# R7FA4L1BD register map
Vendor: Renesas Electronics Corporation; Series: RA4; File version: 0.90.02
CPU: CM33 r0p4, little endian, MPU, FPU, VTOR, 4 interrupt priority bits, 96 interrupts
Registers are 32-bit, read-write, reset 0x0 unless marked. A register's access mark holds for its fields unless they carry their own. Offsets are from the block's base; [hi:lo] are bit positions; {n}, {i} and the like mark numbered series.

## ICU — Interrupt Controller
Base 0x40006000
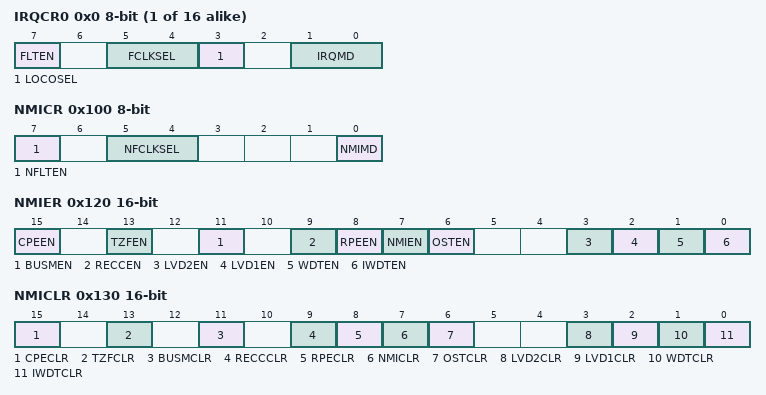
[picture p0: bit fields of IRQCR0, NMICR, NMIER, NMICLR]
{0x0+i} IRQCR{i} (i=0..15) 8-bit — IRQ Control Register {i}
  [7] FLTEN — IRQi Digital Filter Enable
  [5:4] FCLKSEL — IRQi Digital Filter Sampling Clock Select
  [3] LOCOSEL
  [1:0] IRQMD — IRQi Detection Sense Select
0x100 NMICR 8-bit — NMI Pin Interrupt Control Register
  [7] NFLTEN — NMI Digital Filter Enable
  [5:4] NFCLKSEL — NMI Digital Filter Sampling Clock Select
  [0] NMIMD — NMI Detection Set
0x120 NMIER 16-bit — Non,Maskable Interrupt Enable Register
  [15] CPEEN
  [13] TZFEN
  [11] BUSMEN — Bus Master MPU Error Interrupt Enable
  [9] RECCEN — SRAM ECC Error Interrupt Enable
  [8] RPEEN — SRAM Parity Error Interrupt Enable
  [7] NMIEN — NMI Pin Interrupt Enable
  [6] OSTEN — Main Clock Oscillation Stop Detection Interrupt Enable
  [3] LVD2EN — Voltage monitor 2 Interrupt Enable
  [2] LVD1EN — Voltage monitor 1 Interrupt Enable
  [1] WDTEN — WDT Underflow/Refresh Error Interrupt Enable
  [0] IWDTEN — IWDT Underflow/Refresh Error Interrupt Enable
0x130 NMICLR 16-bit — Non,Maskable Interrupt Status Clear Register
  [15] CPECLR
  [13] TZFCLR
  [11] BUSMCLR — Bus Master MPU Error Interrupt Status Flag Clear
  [9] RECCCLR — SRAM ECC Error Interrupt Status Flag Clear
  [8] RPECLR — SRAM Parity Error Interrupt Status Flag Clear
  [7] NMICLR — NMI Pin Interrupt Status Flag Clear
  [6] OSTCLR — Oscillation Stop Detection Interrupt Status Flag Clear
  [3] LVD2CLR — Voltage Monitor 2 Interrupt Status Flag Clear
  [2] LVD1CLR — Voltage Monitor 1 Interrupt Status Flag Clear
  [1] WDTCLR — WDT Underflow/Refresh Error Interrupt Status Flag Clear
  [0] IWDTCLR — IWDT Underflow/Refresh Error Interrupt Status Flag Clear
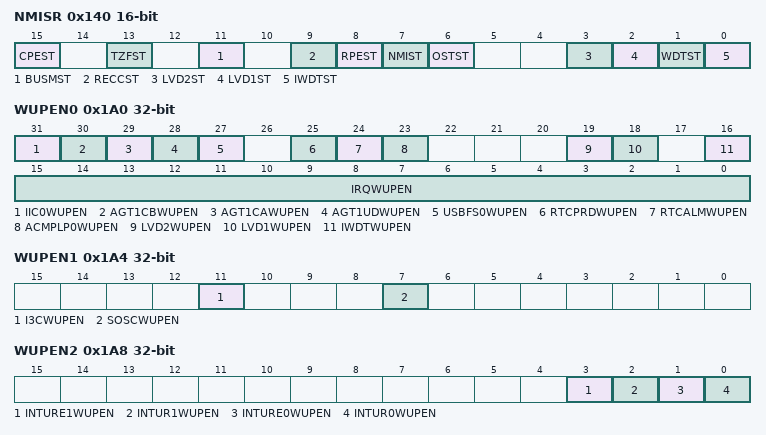
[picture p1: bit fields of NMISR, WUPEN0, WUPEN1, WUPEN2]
0x140 NMISR 16-bit ro — Non,Maskable Interrupt Status Register
  [15] CPEST
  [13] TZFST
  [11] BUSMST — Bus Master MPU Error Interrupt Status Flag
  [9] RECCST — SRAM ECC Error Interrupt Status Flag
  [8] RPEST — SRAM Parity Error Interrupt Status Flag
  [7] NMIST — NMI Pin Interrupt Status Flag
  [6] OSTST — Main Clock Oscillation Stop Detection Interrupt Status Flag
  [3] LVD2ST — Voltage Monitor 2 Interrupt Status Flag
  [2] LVD1ST — Voltage Monitor 1 Interrupt Status Flag
  [1] WDTST — WDT Underflow/Refresh Error Interrupt Status Flag
  [0] IWDTST — IWDT Underflow/Refresh Error Interrupt Status Flag
0x1A0 WUPEN0 — Wake Up Interrupt Enable Register 0
  [31] IIC0WUPEN — IIC0 Address Match Interrupt Software Standby/Snooze Mode Returns Enable Bit
  [30] AGT1CBWUPEN — AGT1 Compare Match B Interrupt Software Standby/Snooze Mode Returns Enable Bit
  [29] AGT1CAWUPEN — AGT1 Compare Match A Interrupt Software Standby/Snooze Mode Returns Enable Bit
  [28] AGT1UDWUPEN — AGT1 Underflow Interrupt Software Standby/Snooze Mode Returns Enable Bit
  [27] USBFS0WUPEN — USBFS Interrupt Software Standby/Snooze Mode Returns Enable Bit
  [25] RTCPRDWUPEN — RTC Period Interrupt Software Standby/Snooze Mode Returns Enable Bit
  [24] RTCALMWUPEN — RTC Alarm Interrupt Software Standby/Snooze Mode Returns Enable Bit
  [23] ACMPLP0WUPEN — ACMPLP0 Interrupt Software Standby/Snooze Mode Returns Enable Bit
  [19] LVD2WUPEN — LVD2 Interrupt Software Standby/Snooze Mode Returns Enable Bit
  [18] LVD1WUPEN — LVD1 Interrupt Software Standby/Snooze Mode Returns Enable Bit
  [16] IWDTWUPEN — IWDT Interrupt Software Standby/Snooze Mode Returns Enable Bit
  [15:0] IRQWUPEN — IRQn Interrupt Software Standby/Snooze Mode Returns Enable Bit (n = 0 to 15)
0x1A4 WUPEN1 — Wake Up Interrupt Enable Register 1
  [11] I3CWUPEN — I3C Wakeup Condition Detection Interrupt Software Standby/Snooze Mode Returns Enable Bit
  [7] SOSCWUPEN — Sub Oscillation Stop Detection Interrupt Software Standby/Snooze Mode Returns Enable Bit
0x1A8 WUPEN2 — Wake Up Interrupt Enable Register 2
  [3] INTURE1WUPEN — UARTA1 Reception Communication Error Occurrence Interrupt Software Standby/Snooze Mode Returns Enable Bit
  [2] INTUR1WUPEN — UARTA1 Reception Transfer End Interrupt Software Standby/Snooze Mode Returns Enable Bit
  [1] INTURE0WUPEN — UARTA0 Reception Communication Error Occurrence Interrupt Software Standby/Snooze Mode Returns Enable Bit
  [0] INTUR0WUPEN — UARTA0 Reception Transfer End Interrupt Software Standby/Snooze Mode Returns Enable Bit
0x200 SELSR0 16-bit — SYS Event Link Setting Register
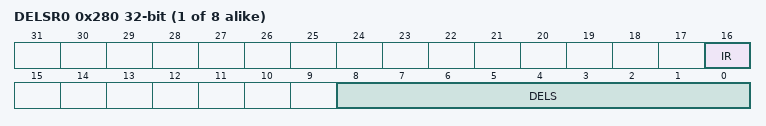
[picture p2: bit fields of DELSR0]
{0x280+4i} DELSR{i} (i=0..7) — DMAC Event Link Setting Register {i}
  [16] IR — DMAC Activation Request Status Flag
  [8:0] DELS — DMAC Event Link Select
{0x300+4i} IELSR{i} (i=0..63) — ICU Event Link Setting Register {i}
